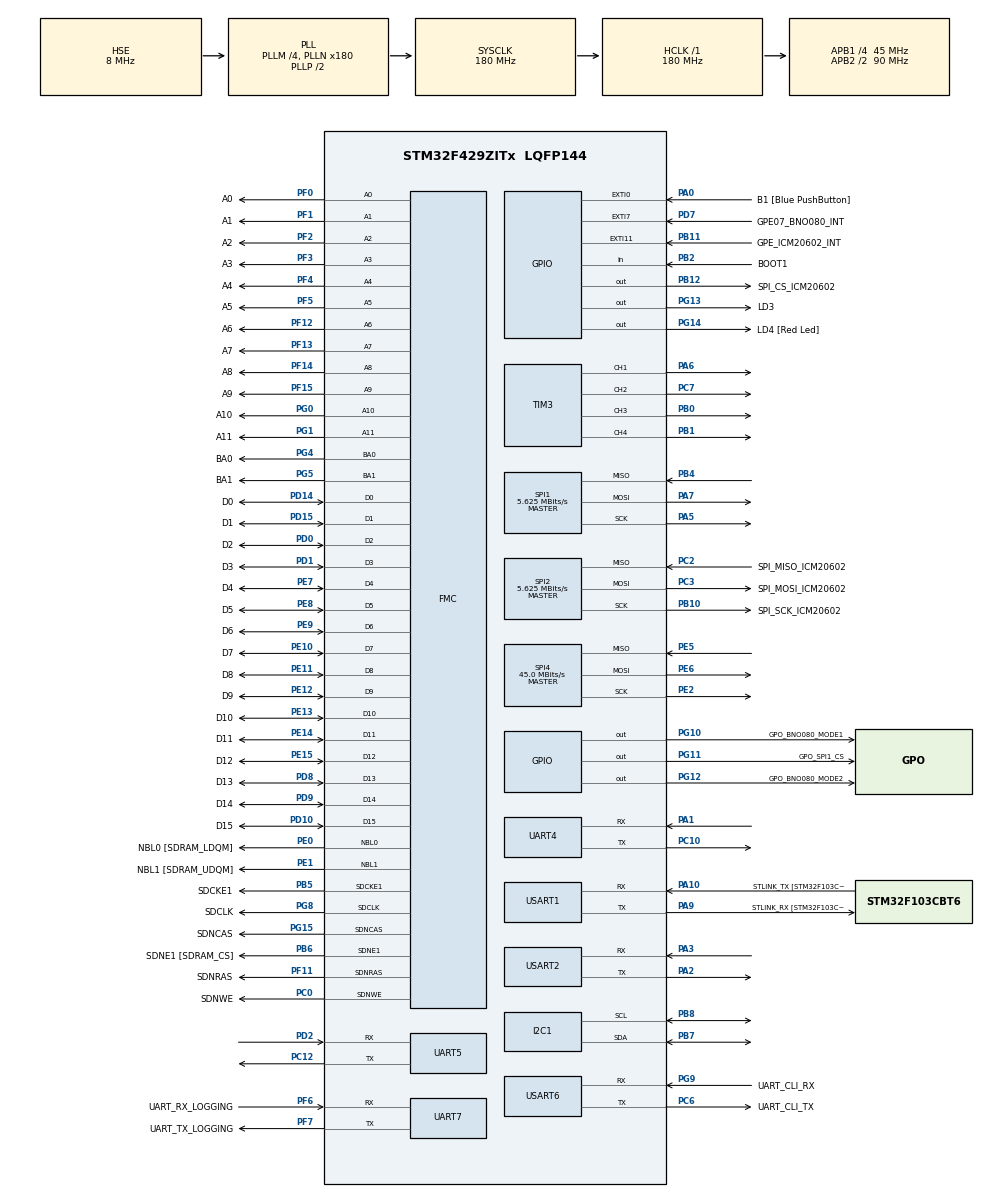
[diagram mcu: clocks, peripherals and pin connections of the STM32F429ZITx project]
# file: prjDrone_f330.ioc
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FMC.CASLatency1=FMC_SDRAM_CAS_LATENCY_3
FMC.ExitSelfRefreshDelay1=7
FMC.LoadToActiveDelay1=2
FMC.RCDDelay1=2
FMC.RPDelay1=2
FMC.RPDelay2=2
FMC.ReadBurst1=FMC_SDRAM_RBURST_DISABLE
FMC.ReadPipeDelay1=FMC_SDRAM_RPIPE_DELAY_1
FMC.ReadPipeDelay2=FMC_SDRAM_RPIPE_DELAY_1
FMC.RowCycleDelay1=7
FMC.RowCycleDelay2=7
FMC.SDClockPeriod1=FMC_SDRAM_CLOCK_PERIOD_2
FMC.SDClockPeriod2=FMC_SDRAM_CLOCK_PERIOD_2
FMC.SelfRefreshTime1=4
FMC.WriteRecoveryTime1=3
Mcu.Family=STM32F4
Mcu.Name=STM32F429ZITx
Mcu.Package=LQFP144
NVIC.EXTI9_5_IRQn=true\:5\:0\:true\:false\:true\:true\:true\:true
NVIC.PriorityGroup=NVIC_PRIORITYGROUP_4
NVIC.TIM7_IRQn=true\:5\:0\:true\:false\:true\:true\:true\:true
NVIC.USART6_IRQn=true\:5\:0\:true\:false\:true\:true\:true\:true
PA0/WKUP.GPIO_Label=B1 [Blue PushButton]
PA0/WKUP.GPIO_ModeDefaultEXTI=GPIO_MODE_EVT_RISING
PA0/WKUP.GPIO_PuPd=GPIO_NOPULL
PA0/WKUP.Signal=GPXTI0
PA1.Mode=Asynchronous
PA1.Signal=UART4_RX
PA10.GPIO_Label=STLINK_TX [STM32F103CBT6_PA2]
PA10.Mode=Asynchronous
PA10.Signal=USART1_RX
PA13.GPIO_Label=SWDIO
PA13.Mode=Serial_Wire
PA13.Signal=SYS_JTMS-SWDIO
PA14.GPIO_Label=SWCLK
PA14.Mode=Serial_Wire
PA14.Signal=SYS_JTCK-SWCLK
PA2.Mode=Asynchronous
PA2.Signal=USART2_TX
PA3.Mode=Asynchronous
PA3.Signal=USART2_RX
PA5.Mode=Full_Duplex_Master
PA5.Signal=SPI1_SCK
PA6.Signal=S_TIM3_CH1
PA7.Mode=Full_Duplex_Master
PA7.Signal=SPI1_MOSI
PA9.GPIO_Label=STLINK_RX [STM32F103CBT6_PA3]
PA9.Mode=Asynchronous
PA9.Signal=USART1_TX
PB0.Signal=S_TIM3_CH3
PB1.Signal=S_TIM3_CH4
PB10.GPIO_Label=SPI_SCK_ICM20602
PB10.Mode=Full_Duplex_Master
PB10.Signal=SPI2_SCK
PB11.GPIO_Label=GPE_ICM20602_INT
PB11.Signal=GPXTI11
PB12.GPIO_Label=SPI_CS_ICM20602
PB12.Signal=GPIO_Output
PB2/BOOT1.GPIO_Label=BOOT1
PB2/BOOT1.GPIO_Mode=GPIO_MODE_INPUT
PB2/BOOT1.GPIO_PuPd=GPIO_NOPULL
PB2/BOOT1.Signal=GPIO_Input
PB4.Mode=Full_Duplex_Master
PB4.Signal=SPI1_MISO
PB5.GPIO_Label=SDCKE1
PB5.GPIO_Mode=GPIO_MODE_AF_PP
PB5.GPIO_PuPd=GPIO_NOPULL
PB5.GPIO_Speed=GPIO_SPEED_FREQ_VERY_HIGH
PB5.Mode=SdramChipSelect2_1
PB5.Signal=FMC_SDCKE1
PB6.GPIO_Label=SDNE1 [SDRAM_CS]
PB6.GPIO_Mode=GPIO_MODE_AF_PP
PB6.GPIO_PuPd=GPIO_NOPULL
PB6.GPIO_Speed=GPIO_SPEED_FREQ_VERY_HIGH
PB6.Mode=SdramChipSelect2_1
PB6.Signal=FMC_SDNE1
PB7.Mode=I2C
PB7.Signal=I2C1_SDA
PB8.Mode=I2C
PB8.Signal=I2C1_SCL
PC0.GPIO_Label=SDNWE
PC0.GPIO_Mode=GPIO_MODE_AF_PP
PC0.GPIO_PuPd=GPIO_NOPULL
PC0.GPIO_Speed=GPIO_SPEED_FREQ_VERY_HIGH
PC0.Signal=FMC_SDNWE
PC10.Mode=Asynchronous
PC10.Signal=UART4_TX
PC12.Mode=Asynchronous
PC12.Signal=UART5_TX
PC2.GPIO_Label=SPI_MISO_ICM20602
PC2.Mode=Full_Duplex_Master
PC2.Signal=SPI2_MISO
PC3.GPIO_Label=SPI_MOSI_ICM20602
PC3.Mode=Full_Duplex_Master
PC3.Signal=SPI2_MOSI
PC6.GPIO_Label=UART_CLI_TX
PC6.Mode=Asynchronous
PC6.Signal=USART6_TX
PC7.Signal=S_TIM3_CH2
PD0.GPIO_Label=D2
PD0.GPIO_Mode=GPIO_MODE_AF_PP
PD0.GPIO_PuPd=GPIO_NOPULL
PD0.GPIO_Speed=GPIO_SPEED_FREQ_VERY_HIGH
PD0.Signal=FMC_D2_DA2
PD1.GPIO_Label=D3
PD1.GPIO_Mode=GPIO_MODE_AF_PP
PD1.GPIO_PuPd=GPIO_NOPULL
PD1.GPIO_Speed=GPIO_SPEED_FREQ_VERY_HIGH
PD1.Signal=FMC_D3_DA3
PD10.GPIO_Label=D15
PD10.GPIO_Mode=GPIO_MODE_AF_PP
PD10.GPIO_PuPd=GPIO_NOPULL
PD10.GPIO_Speed=GPIO_SPEED_FREQ_VERY_HIGH
PD10.Signal=FMC_D15_DA15
PD14.GPIO_Label=D0
PD14.GPIO_Mode=GPIO_MODE_AF_PP
PD14.GPIO_PuPd=GPIO_NOPULL
PD14.GPIO_Speed=GPIO_SPEED_FREQ_VERY_HIGH
PD14.Signal=FMC_D0_DA0
PD15.GPIO_Label=D1
PD15.GPIO_Mode=GPIO_MODE_AF_PP
PD15.GPIO_PuPd=GPIO_NOPULL
PD15.GPIO_Speed=GPIO_SPEED_FREQ_VERY_HIGH
PD15.Signal=FMC_D1_DA1
PD2.Mode=Asynchronous
PD2.Signal=UART5_RX
PD7.GPIO_Label=GPE07_BNO080_INT
PD7.Signal=GPXTI7
PD8.GPIO_Label=D13
PD8.GPIO_Mode=GPIO_MODE_AF_PP
PD8.GPIO_PuPd=GPIO_NOPULL
PD8.GPIO_Speed=GPIO_SPEED_FREQ_VERY_HIGH
PD8.Signal=FMC_D13_DA13
PD9.GPIO_Label=D14
PD9.GPIO_Mode=GPIO_MODE_AF_PP
PD9.GPIO_PuPd=GPIO_NOPULL
PD9.GPIO_Speed=GPIO_SPEED_FREQ_VERY_HIGH
PD9.Signal=FMC_D14_DA14
PE0.GPIO_Label=NBL0 [SDRAM_LDQM]
PE0.GPIO_Mode=GPIO_MODE_AF_PP
PE0.GPIO_PuPd=GPIO_NOPULL
PE0.GPIO_Speed=GPIO_SPEED_FREQ_VERY_HIGH
PE0.Signal=FMC_NBL0
PE1.GPIO_Label=NBL1 [SDRAM_UDQM]
PE1.GPIO_Mode=GPIO_MODE_AF_PP
PE1.GPIO_PuPd=GPIO_NOPULL
PE1.GPIO_Speed=GPIO_SPEED_FREQ_VERY_HIGH
PE1.Signal=FMC_NBL1
PE10.GPIO_Label=D7
PE10.GPIO_Mode=GPIO_MODE_AF_PP
PE10.GPIO_PuPd=GPIO_NOPULL
PE10.GPIO_Speed=GPIO_SPEED_FREQ_VERY_HIGH
PE10.Signal=FMC_D7_DA7
PE11.GPIO_Label=D8
PE11.GPIO_Mode=GPIO_MODE_AF_PP
PE11.GPIO_PuPd=GPIO_NOPULL
PE11.GPIO_Speed=GPIO_SPEED_FREQ_VERY_HIGH
PE11.Signal=FMC_D8_DA8
PE12.GPIO_Label=D9
PE12.GPIO_Mode=GPIO_MODE_AF_PP
PE12.GPIO_PuPd=GPIO_NOPULL
PE12.GPIO_Speed=GPIO_SPEED_FREQ_VERY_HIGH
PE12.Signal=FMC_D9_DA9
PE13.GPIO_Label=D10
PE13.GPIO_Mode=GPIO_MODE_AF_PP
PE13.GPIO_PuPd=GPIO_NOPULL
PE13.GPIO_Speed=GPIO_SPEED_FREQ_VERY_HIGH
PE13.Signal=FMC_D10_DA10
PE14.GPIO_Label=D11
PE14.GPIO_Mode=GPIO_MODE_AF_PP
PE14.GPIO_PuPd=GPIO_NOPULL
PE14.GPIO_Speed=GPIO_SPEED_FREQ_VERY_HIGH
PE14.Signal=FMC_D11_DA11
PE15.GPIO_Label=D12
PE15.GPIO_Mode=GPIO_MODE_AF_PP
PE15.GPIO_PuPd=GPIO_NOPULL
PE15.GPIO_Speed=GPIO_SPEED_FREQ_VERY_HIGH
PE15.Signal=FMC_D12_DA12
PE2.Mode=Full_Duplex_Master
PE2.Signal=SPI4_SCK
PE5.Mode=Full_Duplex_Master
PE5.Signal=SPI4_MISO
PE6.Mode=Full_Duplex_Master
PE6.Signal=SPI4_MOSI
PE7.GPIO_Label=D4
PE7.GPIO_Mode=GPIO_MODE_AF_PP
PE7.GPIO_PuPd=GPIO_NOPULL
PE7.GPIO_Speed=GPIO_SPEED_FREQ_VERY_HIGH
PE7.Signal=FMC_D4_DA4
PE8.GPIO_Label=D5
PE8.GPIO_Mode=GPIO_MODE_AF_PP
PE8.GPIO_PuPd=GPIO_NOPULL
PE8.GPIO_Speed=GPIO_SPEED_FREQ_VERY_HIGH
PE8.Signal=FMC_D5_DA5
PE9.GPIO_Label=D6
PE9.GPIO_Mode=GPIO_MODE_AF_PP
PE9.GPIO_PuPd=GPIO_NOPULL
PE9.GPIO_Speed=GPIO_SPEED_FREQ_VERY_HIGH
PE9.Signal=FMC_D6_DA6
PF0.GPIO_Label=A0
PF0.GPIO_Mode=GPIO_MODE_AF_PP
PF0.GPIO_PuPd=GPIO_NOPULL
PF0.GPIO_Speed=GPIO_SPEED_FREQ_VERY_HIGH
PF0.Signal=FMC_A0
PF1.GPIO_Label=A1
PF1.GPIO_Mode=GPIO_MODE_AF_PP
PF1.GPIO_PuPd=GPIO_NOPULL
PF1.GPIO_Speed=GPIO_SPEED_FREQ_VERY_HIGH
PF1.Signal=FMC_A1
PF11.GPIO_Label=SDNRAS
PF11.GPIO_Mode=GPIO_MODE_AF_PP
PF11.GPIO_PuPd=GPIO_NOPULL
PF11.GPIO_Speed=GPIO_SPEED_FREQ_VERY_HIGH
PF11.Signal=FMC_SDNRAS
PF12.GPIO_Label=A6
PF12.GPIO_Mode=GPIO_MODE_AF_PP
PF12.GPIO_PuPd=GPIO_NOPULL
PF12.GPIO_Speed=GPIO_SPEED_FREQ_VERY_HIGH
PF12.Signal=FMC_A6
PF13.GPIO_Label=A7
PF13.GPIO_Mode=GPIO_MODE_AF_PP
PF13.GPIO_PuPd=GPIO_NOPULL
PF13.GPIO_Speed=GPIO_SPEED_FREQ_VERY_HIGH
PF13.Signal=FMC_A7
PF14.GPIO_Label=A8
PF14.GPIO_Mode=GPIO_MODE_AF_PP
PF14.GPIO_PuPd=GPIO_NOPULL
PF14.GPIO_Speed=GPIO_SPEED_FREQ_VERY_HIGH
PF14.Signal=FMC_A8
PF15.GPIO_Label=A9
PF15.GPIO_Mode=GPIO_MODE_AF_PP
PF15.GPIO_PuPd=GPIO_NOPULL
PF15.GPIO_Speed=GPIO_SPEED_FREQ_VERY_HIGH
PF15.Signal=FMC_A9
PF2.GPIO_Label=A2
PF2.GPIO_Mode=GPIO_MODE_AF_PP
PF2.GPIO_PuPd=GPIO_NOPULL
PF2.GPIO_Speed=GPIO_SPEED_FREQ_VERY_HIGH
PF2.Signal=FMC_A2
PF3.GPIO_Label=A3
PF3.GPIO_Mode=GPIO_MODE_AF_PP
PF3.GPIO_PuPd=GPIO_NOPULL
PF3.GPIO_Speed=GPIO_SPEED_FREQ_VERY_HIGH
PF3.Signal=FMC_A3
PF4.GPIO_Label=A4
PF4.GPIO_Mode=GPIO_MODE_AF_PP
PF4.GPIO_PuPd=GPIO_NOPULL
PF4.GPIO_Speed=GPIO_SPEED_FREQ_VERY_HIGH
PF4.Signal=FMC_A4
PF5.GPIO_Label=A5
PF5.GPIO_Mode=GPIO_MODE_AF_PP
PF5.GPIO_PuPd=GPIO_NOPULL
PF5.GPIO_Speed=GPIO_SPEED_FREQ_VERY_HIGH
PF5.Signal=FMC_A5
PF6.GPIO_Label=UART_RX_LOGGING
PF6.Mode=Asynchronous
PF6.Signal=UART7_RX
PF7.GPIO_Label=UART_TX_LOGGING
PF7.Mode=Asynchronous
PF7.Signal=UART7_TX
PG0.GPIO_Label=A10
PG0.GPIO_Mode=GPIO_MODE_AF_PP
PG0.GPIO_PuPd=GPIO_NOPULL
PG0.GPIO_Speed=GPIO_SPEED_FREQ_VERY_HIGH
PG0.Signal=FMC_A10
PG1.GPIO_Label=A11
PG1.GPIO_Mode=GPIO_MODE_AF_PP
PG1.GPIO_PuPd=GPIO_NOPULL
PG1.GPIO_Speed=GPIO_SPEED_FREQ_VERY_HIGH
PG1.Signal=FMC_A11
PG10.GPIO_Label=GPO_BNO080_MODE1
PG10.Signal=GPIO_Output
PG11.GPIO_Label=GPO_SPI1_CS
PG11.Signal=GPIO_Output
PG12.GPIO_Label=GPO_BNO080_MODE2
PG12.Signal=GPIO_Output
PG13.GPIO_Label=LD3
PG13.Signal=GPIO_Output
PG14.GPIO_Label=LD4 [Red Led]
PG14.GPIO_PuPd=GPIO_NOPULL
PG14.GPIO_Speed=GPIO_SPEED_FREQ_LOW
PG14.Signal=GPIO_Output
PG15.GPIO_Label=SDNCAS
PG15.GPIO_Mode=GPIO_MODE_AF_PP
PG15.GPIO_PuPd=GPIO_NOPULL
PG15.GPIO_Speed=GPIO_SPEED_FREQ_VERY_HIGH
PG15.Signal=FMC_SDNCAS
PG4.GPIO_Label=BA0
PG4.GPIO_Mode=GPIO_MODE_AF_PP
PG4.GPIO_PuPd=GPIO_NOPULL
PG4.GPIO_Speed=GPIO_SPEED_FREQ_VERY_HIGH
PG4.Signal=FMC_A14_BA0
PG5.GPIO_Label=BA1
PG5.GPIO_Mode=GPIO_MODE_AF_PP
PG5.GPIO_PuPd=GPIO_NOPULL
PG5.GPIO_Speed=GPIO_SPEED_FREQ_VERY_HIGH
PG5.Signal=FMC_A15_BA1
PG8.GPIO_Label=SDCLK
PG8.GPIO_Mode=GPIO_MODE_AF_PP
PG8.GPIO_PuPd=GPIO_NOPULL
PG8.GPIO_Speed=GPIO_SPEED_FREQ_VERY_HIGH
PG8.Signal=FMC_SDCLK
PG9.GPIO_Label=UART_CLI_RX
PG9.Mode=Asynchronous
PG9.Signal=USART6_RX
PH0/OSC_IN.GPIO_Label=PH0-OSC_IN
PH0/OSC_IN.Mode=HSE-External-Oscillator
PH0/OSC_IN.Signal=RCC_OSC_IN
PH1/OSC_OUT.GPIO_Label=PH1-OSC_OUT
PH1/OSC_OUT.Mode=HSE-External-Oscillator
PH1/OSC_OUT.Signal=RCC_OSC_OUT
ProjectManager.HeapSize=0x200
ProjectManager.StackSize=0x400
ProjectManager.TargetToolchain=CMake
RCC.48MHZClocksFreq_Value=120000000
RCC.AHBFreq_Value=180000000
RCC.APB1CLKDivider=RCC_HCLK_DIV4
RCC.APB1Freq_Value=45000000
RCC.APB1TimFreq_Value=90000000
RCC.APB2CLKDivider=RCC_HCLK_DIV2
RCC.APB2Freq_Value=90000000
RCC.APB2TimFreq_Value=180000000
RCC.CortexFreq_Value=180000000
RCC.HCLKFreq_Value=180000000
RCC.HSE_VALUE=8000000
RCC.HSI_VALUE=16000000
RCC.LSE_VALUE=32768
RCC.PLLM=4
RCC.PLLN=180
RCC.PLLQ=3
RCC.PLLSAIN=50
RCC.PLLSourceVirtual=RCC_PLLSOURCE_HSE
RCC.SYSCLKFreq_VALUE=180000000
RCC.SYSCLKSource=RCC_SYSCLKSOURCE_PLLCLK
RCC.VCOOutputFreq_Value=360000000
SH.FMC_A0.0=FMC_A0,12b-sda1
SH.FMC_A1.0=FMC_A1,12b-sda1
SH.FMC_A10.0=FMC_A10,12b-sda1
SH.FMC_A11.0=FMC_A11,12b-sda1
SH.FMC_A14_BA0.0=FMC_BA0,FourSdramBanks1
SH.FMC_A15_BA1.0=FMC_BA1,FourSdramBanks1
SH.FMC_A2.0=FMC_A2,12b-sda1
SH.FMC_A3.0=FMC_A3,12b-sda1
SH.FMC_A4.0=FMC_A4,12b-sda1
SH.FMC_A5.0=FMC_A5,12b-sda1
SH.FMC_A6.0=FMC_A6,12b-sda1
SH.FMC_A7.0=FMC_A7,12b-sda1
SH.FMC_A8.0=FMC_A8,12b-sda1
SH.FMC_A9.0=FMC_A9,12b-sda1
SH.FMC_D0_DA0.0=FMC_D0,sd-16b-d1
SH.FMC_D10_DA10.0=FMC_D10,sd-16b-d1
SH.FMC_D11_DA11.0=FMC_D11,sd-16b-d1
SH.FMC_D12_DA12.0=FMC_D12,sd-16b-d1
SH.FMC_D13_DA13.0=FMC_D13,sd-16b-d1
SH.FMC_D14_DA14.0=FMC_D14,sd-16b-d1
SH.FMC_D15_DA15.0=FMC_D15,sd-16b-d1
SH.FMC_D1_DA1.0=FMC_D1,sd-16b-d1
SH.FMC_D2_DA2.0=FMC_D2,sd-16b-d1
SH.FMC_D3_DA3.0=FMC_D3,sd-16b-d1
SH.FMC_D4_DA4.0=FMC_D4,sd-16b-d1
SH.FMC_D5_DA5.0=FMC_D5,sd-16b-d1
SH.FMC_D6_DA6.0=FMC_D6,sd-16b-d1
SH.FMC_D7_DA7.0=FMC_D7,sd-16b-d1
SH.FMC_D8_DA8.0=FMC_D8,sd-16b-d1
SH.FMC_D9_DA9.0=FMC_D9,sd-16b-d1
SH.FMC_NBL0.0=FMC_NBL0,Sd2ByteEnable1
SH.FMC_NBL1.0=FMC_NBL1,Sd2ByteEnable1
SH.FMC_SDCLK.0=FMC_SDCLK,12b-sda1
SH.FMC_SDNCAS.0=FMC_SDNCAS,12b-sda1
SH.FMC_SDNRAS.0=FMC_SDNRAS,12b-sda1
SH.FMC_SDNWE.0=FMC_SDNWE,12b-sda1
SH.S_TIM3_CH1.0=TIM3_CH1,PWM Generation1 CH1
SH.S_TIM3_CH2.0=TIM3_CH2,PWM Generation2 CH2
SH.S_TIM3_CH3.0=TIM3_CH3,PWM Generation3 CH3
SH.S_TIM3_CH4.0=TIM3_CH4,PWM Generation4 CH4
SPI1.BaudRatePrescaler=SPI_BAUDRATEPRESCALER_16
SPI1.CLKPhase=SPI_PHASE_2EDGE
SPI1.CLKPolarity=SPI_POLARITY_HIGH
SPI1.CalculateBaudRate=5.625 MBits/s
SPI1.Direction=SPI_DIRECTION_2LINES
SPI1.Mode=SPI_MODE_MASTER
SPI1.VirtualType=VM_MASTER
SPI2.BaudRatePrescaler=SPI_BAUDRATEPRESCALER_8
SPI2.CLKPhase=SPI_PHASE_1EDGE
SPI2.CLKPolarity=SPI_POLARITY_LOW
SPI2.CalculateBaudRate=5.625 MBits/s
SPI2.Direction=SPI_DIRECTION_2LINES
SPI2.Mode=SPI_MODE_MASTER
SPI2.VirtualType=VM_MASTER
SPI4.CalculateBaudRate=45.0 MBits/s
SPI4.Direction=SPI_DIRECTION_2LINES
SPI4.Mode=SPI_MODE_MASTER
SPI4.VirtualType=VM_MASTER
TIM3.Channel-PWM\ Generation1\ CH1=TIM_CHANNEL_1
TIM3.Channel-PWM\ Generation2\ CH2=TIM_CHANNEL_2
TIM3.Channel-PWM\ Generation3\ CH3=TIM_CHANNEL_3
TIM3.Channel-PWM\ Generation4\ CH4=TIM_CHANNEL_4
TIM7.Period=1000-1
TIM7.Prescaler=90-1
UART4.VirtualMode=Asynchronous
UART5.VirtualMode=Asynchronous
UART7.VirtualMode=Asynchronous
USART1.VirtualMode=VM_ASYNC
USART2.VirtualMode=VM_ASYNC
USART6.VirtualMode=VM_ASYNC
VP_CRC_VS_CRC.Mode=CRC_Activate
VP_TIM3_VS_ClockSourceINT.Mode=Internal
VP_TIM6_VS_ClockSourceINT.Mode=Enable_Timer
VP_TIM7_VS_ClockSourceINT.Mode=Enable_Timer
board=STM32F429I-DISC1

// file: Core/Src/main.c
/* USER CODE BEGIN Header */
/**
  ******************************************************************************
  * @file           : main.c
  * @brief          : Main program body
  ******************************************************************************
  * @attention
  *
  * Copyright (c) 2025 STMicroelectronics.
  * All rights reserved.
  *
  * This software is licensed under terms that can be found in the LICENSE file
  * in the root directory of this software component.
  * If no LICENSE file comes with this software, it is provided AS-IS.
  *
  ******************************************************************************
  */

/* USER CODE END Header */
#include "main.h"

/* USER CODE BEGIN Includes */
#include "entry.h"
#include "tiny_printf.h"
#include "ICM20602.h"
#include "taskSensImu.h"
/* USER CODE END Includes */

CRC_HandleTypeDef hcrc;

I2C_HandleTypeDef hi2c1;

SPI_HandleTypeDef hspi1;
SPI_HandleTypeDef hspi2;
SPI_HandleTypeDef hspi4;

TIM_HandleTypeDef htim3;
TIM_HandleTypeDef htim6;
TIM_HandleTypeDef htim7;

UART_HandleTypeDef huart4;
UART_HandleTypeDef huart5;
UART_HandleTypeDef huart7;
UART_HandleTypeDef huart1;
UART_HandleTypeDef huart2;
UART_HandleTypeDef huart6;

SDRAM_HandleTypeDef hsdram1;

/* USER CODE BEGIN PV */
uint8_t g_ucKernelStarted = 0;

/* USER CODE END PV */

void SystemClock_Config(void);
static void MX_GPIO_Init(void);
static void MX_CRC_Init(void);
static void MX_FMC_Init(void);
static void MX_UART7_Init(void);
static void MX_USART1_UART_Init(void);
static void MX_USART6_UART_Init(void);
static void MX_TIM6_Init(void);
static void MX_TIM7_Init(void);
static void MX_I2C1_Init(void);
static void MX_SPI2_Init(void);
static void MX_UART4_Init(void);
static void MX_UART5_Init(void);
static void MX_USART2_UART_Init(void);
static void MX_SPI1_Init(void);
static void MX_TIM3_Init(void);
static void MX_SPI4_Init(void);

/* USER CODE BEGIN 0 */
void _putchar(char character)
{
  // send char to console etc.
  HAL_UART_Transmit(&huart1, (uint8_t*)(&character), 1, 20) ;
}
/* USER CODE END 0 */

int main(void)
{

  /* MCU Configuration--------------------------------------------------------*/

  /* Reset of all peripherals, Initializes the Flash interface and the Systick. */
  HAL_Init();

  /* Configure the system clock */
  SystemClock_Config();

  /* Initialize all configured peripherals */
  MX_GPIO_Init();
  MX_CRC_Init();
  MX_FMC_Init();
  MX_UART7_Init();
  MX_USART1_UART_Init();
  MX_USART6_UART_Init();
  MX_TIM6_Init();
  MX_TIM7_Init();
  MX_I2C1_Init();
  MX_SPI2_Init();
  MX_UART4_Init();
  MX_UART5_Init();
  MX_USART2_UART_Init();
  MX_SPI1_Init();
  MX_TIM3_Init();
  MX_SPI4_Init();
  /* USER CODE BEGIN 2 */

  HAL_GPIO_WritePin(SPI_CS_ICM20602_GPIO_Port, SPI_CS_ICM20602_Pin, GPIO_PIN_SET);
  HAL_Delay(1000);

  // while(1){
  //   HAL_Delay(5);
  //   ICM20602_Get3AxisGyroRawData(g_ausGyro);
  //   printf("X: %d, Y: %d, Z: %d\r\n",g_ausGyro[0], g_ausGyro[1],g_ausGyro[2] );
  // }

  EntryPoint();
  printf("Kernel Start Ready~\r\n");
  g_ucKernelStarted = 1;
  vTaskStartScheduler();

  /* USER CODE END 2 */

  /* Infinite loop */
  while (1)
  {

  }
}

void SystemClock_Config(void)
{
  RCC_OscInitTypeDef RCC_OscInitStruct = {0};
  RCC_ClkInitTypeDef RCC_ClkInitStruct = {0};

  /** Configure the main internal regulator output voltage
  */
  __HAL_RCC_PWR_CLK_ENABLE();
  __HAL_PWR_VOLTAGESCALING_CONFIG(PWR_REGULATOR_VOLTAGE_SCALE1);

  /** Initializes the RCC Oscillators according to the specified parameters
  * in the RCC_OscInitTypeDef structure.
  */
  RCC_OscInitStruct.OscillatorType = RCC_OSCILLATORTYPE_HSE;
  RCC_OscInitStruct.HSEState = RCC_HSE_ON;
  RCC_OscInitStruct.PLL.PLLState = RCC_PLL_ON;
  RCC_OscInitStruct.PLL.PLLSource = RCC_PLLSOURCE_HSE;
  RCC_OscInitStruct.PLL.PLLM = 4;
  RCC_OscInitStruct.PLL.PLLN = 180;
  RCC_OscInitStruct.PLL.PLLP = RCC_PLLP_DIV2;
  RCC_OscInitStruct.PLL.PLLQ = 3;
  if (HAL_RCC_OscConfig(&RCC_OscInitStruct) != HAL_OK)
  {
    Error_Handler();
  }

  /** Activate the Over-Drive mode
  */
  if (HAL_PWREx_EnableOverDrive() != HAL_OK)
  {
    Error_Handler();
  }

  /** Initializes the CPU, AHB and APB buses clocks
  */
  RCC_ClkInitStruct.ClockType = RCC_CLOCKTYPE_HCLK|RCC_CLOCKTYPE_SYSCLK
                              |RCC_CLOCKTYPE_PCLK1|RCC_CLOCKTYPE_PCLK2;
  RCC_ClkInitStruct.SYSCLKSource = RCC_SYSCLKSOURCE_PLLCLK;
  RCC_ClkInitStruct.AHBCLKDivider = RCC_SYSCLK_DIV1;
  RCC_ClkInitStruct.APB1CLKDivider = RCC_HCLK_DIV4;
  RCC_ClkInitStruct.APB2CLKDivider = RCC_HCLK_DIV2;

  if (HAL_RCC_ClockConfig(&RCC_ClkInitStruct, FLASH_LATENCY_5) != HAL_OK)
  {
    Error_Handler();
  }
}

static void MX_CRC_Init(void)
{

  hcrc.Instance = CRC;
  if (HAL_CRC_Init(&hcrc) != HAL_OK)
  {
    Error_Handler();
  }

}

static void MX_I2C1_Init(void)
{

  hi2c1.Instance = I2C1;
  hi2c1.Init.ClockSpeed = 100000;
  hi2c1.Init.DutyCycle = I2C_DUTYCYCLE_2;
  hi2c1.Init.OwnAddress1 = 0;
  hi2c1.Init.AddressingMode = I2C_ADDRESSINGMODE_7BIT;
  hi2c1.Init.DualAddressMode = I2C_DUALADDRESS_DISABLE;
  hi2c1.Init.OwnAddress2 = 0;
  hi2c1.Init.GeneralCallMode = I2C_GENERALCALL_DISABLE;
  hi2c1.Init.NoStretchMode = I2C_NOSTRETCH_DISABLE;
  if (HAL_I2C_Init(&hi2c1) != HAL_OK)
  {
    Error_Handler();
  }

  /** Configure Analogue filter
  */
  if (HAL_I2CEx_ConfigAnalogFilter(&hi2c1, I2C_ANALOGFILTER_ENABLE) != HAL_OK)
  {
    Error_Handler();
  }

  /** Configure Digital filter
  */
  if (HAL_I2CEx_ConfigDigitalFilter(&hi2c1, 0) != HAL_OK)
  {
    Error_Handler();
  }

}

static void MX_SPI1_Init(void)
{

  /* SPI1 parameter configuration*/
  hspi1.Instance = SPI1;
  hspi1.Init.Mode = SPI_MODE_MASTER;
  hspi1.Init.Direction = SPI_DIRECTION_2LINES;
  hspi1.Init.DataSize = SPI_DATASIZE_8BIT;
  hspi1.Init.CLKPolarity = SPI_POLARITY_HIGH;
  hspi1.Init.CLKPhase = SPI_PHASE_2EDGE;
  hspi1.Init.NSS = SPI_NSS_SOFT;
  hspi1.Init.BaudRatePrescaler = SPI_BAUDRATEPRESCALER_16;
  hspi1.Init.FirstBit = SPI_FIRSTBIT_MSB;
  hspi1.Init.TIMode = SPI_TIMODE_DISABLE;
  hspi1.Init.CRCCalculation = SPI_CRCCALCULATION_DISABLE;
  hspi1.Init.CRCPolynomial = 10;
  if (HAL_SPI_Init(&hspi1) != HAL_OK)
  {
    Error_Handler();
  }

}

static void MX_SPI2_Init(void)
{

  /* SPI2 parameter configuration*/
  hspi2.Instance = SPI2;
  hspi2.Init.Mode = SPI_MODE_MASTER;
  hspi2.Init.Direction = SPI_DIRECTION_2LINES;
  hspi2.Init.DataSize = SPI_DATASIZE_8BIT;
  hspi2.Init.CLKPolarity = SPI_POLARITY_LOW;
  hspi2.Init.CLKPhase = SPI_PHASE_1EDGE;
  hspi2.Init.NSS = SPI_NSS_SOFT;
  hspi2.Init.BaudRatePrescaler = SPI_BAUDRATEPRESCALER_8;
  hspi2.Init.FirstBit = SPI_FIRSTBIT_MSB;
  hspi2.Init.TIMode = SPI_TIMODE_DISABLE;
  hspi2.Init.CRCCalculation = SPI_CRCCALCULATION_DISABLE;
  hspi2.Init.CRCPolynomial = 10;
  if (HAL_SPI_Init(&hspi2) != HAL_OK)
  {
    Error_Handler();
  }

}

static void MX_SPI4_Init(void)
{

  /* SPI4 parameter configuration*/
  hspi4.Instance = SPI4;
  hspi4.Init.Mode = SPI_MODE_MASTER;
  hspi4.Init.Direction = SPI_DIRECTION_2LINES;
  hspi4.Init.DataSize = SPI_DATASIZE_8BIT;
  hspi4.Init.CLKPolarity = SPI_POLARITY_LOW;
  hspi4.Init.CLKPhase = SPI_PHASE_1EDGE;
  hspi4.Init.NSS = SPI_NSS_SOFT;
  hspi4.Init.BaudRatePrescaler = SPI_BAUDRATEPRESCALER_2;
  hspi4.Init.FirstBit = SPI_FIRSTBIT_MSB;
  hspi4.Init.TIMode = SPI_TIMODE_DISABLE;
  hspi4.Init.CRCCalculation = SPI_CRCCALCULATION_DISABLE;
  hspi4.Init.CRCPolynomial = 10;
  if (HAL_SPI_Init(&hspi4) != HAL_OK)
  {
    Error_Handler();
  }

}

static void MX_TIM3_Init(void)
{

  TIM_ClockConfigTypeDef sClockSourceConfig = {0};
  TIM_MasterConfigTypeDef sMasterConfig = {0};
  TIM_OC_InitTypeDef sConfigOC = {0};

  htim3.Instance = TIM3;
  htim3.Init.Prescaler = 0;
  htim3.Init.CounterMode = TIM_COUNTERMODE_UP;
  htim3.Init.Period = 65535;
  htim3.Init.ClockDivision = TIM_CLOCKDIVISION_DIV1;
  htim3.Init.AutoReloadPreload = TIM_AUTORELOAD_PRELOAD_DISABLE;
  if (HAL_TIM_Base_Init(&htim3) != HAL_OK)
  {
    Error_Handler();
  }
  sClockSourceConfig.ClockSource = TIM_CLOCKSOURCE_INTERNAL;
  if (HAL_TIM_ConfigClockSource(&htim3, &sClockSourceConfig) != HAL_OK)
  {
    Error_Handler();
  }
  if (HAL_TIM_PWM_Init(&htim3) != HAL_OK)
  {
    Error_Handler();
  }
  sMasterConfig.MasterOutputTrigger = TIM_TRGO_RESET;
  sMasterConfig.MasterSlaveMode = TIM_MASTERSLAVEMODE_DISABLE;
  if (HAL_TIMEx_MasterConfigSynchronization(&htim3, &sMasterConfig) != HAL_OK)
  {
    Error_Handler();
  }
  sConfigOC.OCMode = TIM_OCMODE_PWM1;
  sConfigOC.Pulse = 0;
  sConfigOC.OCPolarity = TIM_OCPOLARITY_HIGH;
  sConfigOC.OCFastMode = TIM_OCFAST_DISABLE;
  if (HAL_TIM_PWM_ConfigChannel(&htim3, &sConfigOC, TIM_CHANNEL_1) != HAL_OK)
  {
    Error_Handler();
  }
  if (HAL_TIM_PWM_ConfigChannel(&htim3, &sConfigOC, TIM_CHANNEL_2) != HAL_OK)
  {
    Error_Handler();
  }
  if (HAL_TIM_PWM_ConfigChannel(&htim3, &sConfigOC, TIM_CHANNEL_3) != HAL_OK)
  {
    Error_Handler();
  }
  if (HAL_TIM_PWM_ConfigChannel(&htim3, &sConfigOC, TIM_CHANNEL_4) != HAL_OK)
  {
    Error_Handler();
  }
  HAL_TIM_MspPostInit(&htim3);

}

static void MX_TIM6_Init(void)
{

  TIM_MasterConfigTypeDef sMasterConfig = {0};

  htim6.Instance = TIM6;
  htim6.Init.Prescaler = 0;
  htim6.Init.CounterMode = TIM_COUNTERMODE_UP;
  htim6.Init.Period = 65535;
  htim6.Init.AutoReloadPreload = TIM_AUTORELOAD_PRELOAD_DISABLE;
  if (HAL_TIM_Base_Init(&htim6) != HAL_OK)
  {
    Error_Handler();
  }
  sMasterConfig.MasterOutputTrigger = TIM_TRGO_RESET;
  sMasterConfig.MasterSlaveMode = TIM_MASTERSLAVEMODE_DISABLE;
  if (HAL_TIMEx_MasterConfigSynchronization(&htim6, &sMasterConfig) != HAL_OK)
  {
    Error_Handler();
  }

}

static void MX_TIM7_Init(void)
{

  TIM_MasterConfigTypeDef sMasterConfig = {0};

  htim7.Instance = TIM7;
  htim7.Init.Prescaler = 90-1;
  htim7.Init.CounterMode = TIM_COUNTERMODE_UP;
  htim7.Init.Period = 1000-1;
  htim7.Init.AutoReloadPreload = TIM_AUTORELOAD_PRELOAD_DISABLE;
  if (HAL_TIM_Base_Init(&htim7) != HAL_OK)
  {
    Error_Handler();
  }
  sMasterConfig.MasterOutputTrigger = TIM_TRGO_RESET;
  sMasterConfig.MasterSlaveMode = TIM_MASTERSLAVEMODE_DISABLE;
  if (HAL_TIMEx_MasterConfigSynchronization(&htim7, &sMasterConfig) != HAL_OK)
  {
    Error_Handler();
  }

}

static void MX_UART4_Init(void)
{

  huart4.Instance = UART4;
  huart4.Init.BaudRate = 115200;
  huart4.Init.WordLength = UART_WORDLENGTH_8B;
  huart4.Init.StopBits = UART_STOPBITS_1;
  huart4.Init.Parity = UART_PARITY_NONE;
  huart4.Init.Mode = UART_MODE_TX_RX;
  huart4.Init.HwFlowCtl = UART_HWCONTROL_NONE;
  huart4.Init.OverSampling = UART_OVERSAMPLING_16;
  if (HAL_UART_Init(&huart4) != HAL_OK)
  {
    Error_Handler();
  }

}

static void MX_UART5_Init(void)
{

  huart5.Instance = UART5;
  huart5.Init.BaudRate = 115200;
  huart5.Init.WordLength = UART_WORDLENGTH_8B;
  huart5.Init.StopBits = UART_STOPBITS_1;
  huart5.Init.Parity = UART_PARITY_NONE;
  huart5.Init.Mode = UART_MODE_TX_RX;
  huart5.Init.HwFlowCtl = UART_HWCONTROL_NONE;
  huart5.Init.OverSampling = UART_OVERSAMPLING_16;
  if (HAL_UART_Init(&huart5) != HAL_OK)
  {
    Error_Handler();
  }

}

static void MX_UART7_Init(void)
{

  huart7.Instance = UART7;
  huart7.Init.BaudRate = 115200;
  huart7.Init.WordLength = UART_WORDLENGTH_8B;
  huart7.Init.StopBits = UART_STOPBITS_1;
  huart7.Init.Parity = UART_PARITY_NONE;
  huart7.Init.Mode = UART_MODE_TX_RX;
  huart7.Init.HwFlowCtl = UART_HWCONTROL_NONE;
  huart7.Init.OverSampling = UART_OVERSAMPLING_16;
  if (HAL_UART_Init(&huart7) != HAL_OK)
  {
    Error_Handler();
  }

}

static void MX_USART1_UART_Init(void)
{

  huart1.Instance = USART1;
  huart1.Init.BaudRate = 115200;
  huart1.Init.WordLength = UART_WORDLENGTH_8B;
  huart1.Init.StopBits = UART_STOPBITS_1;
  huart1.Init.Parity = UART_PARITY_NONE;
  huart1.Init.Mode = UART_MODE_TX_RX;
  huart1.Init.HwFlowCtl = UART_HWCONTROL_NONE;
  huart1.Init.OverSampling = UART_OVERSAMPLING_16;
  if (HAL_UART_Init(&huart1) != HAL_OK)
  {
    Error_Handler();
  }

}

static void MX_USART2_UART_Init(void)
{

  huart2.Instance = USART2;
  huart2.Init.BaudRate = 115200;
  huart2.Init.WordLength = UART_WORDLENGTH_8B;
  huart2.Init.StopBits = UART_STOPBITS_1;
  huart2.Init.Parity = UART_PARITY_NONE;
  huart2.Init.Mode = UART_MODE_TX_RX;
  huart2.Init.HwFlowCtl = UART_HWCONTROL_NONE;
  huart2.Init.OverSampling = UART_OVERSAMPLING_16;
  if (HAL_UART_Init(&huart2) != HAL_OK)
  {
    Error_Handler();
  }

}

static void MX_USART6_UART_Init(void)
{

  huart6.Instance = USART6;
  huart6.Init.BaudRate = 115200;
  huart6.Init.WordLength = UART_WORDLENGTH_8B;
  huart6.Init.StopBits = UART_STOPBITS_1;
  huart6.Init.Parity = UART_PARITY_NONE;
  huart6.Init.Mode = UART_MODE_TX_RX;
  huart6.Init.HwFlowCtl = UART_HWCONTROL_NONE;
  huart6.Init.OverSampling = UART_OVERSAMPLING_16;
  if (HAL_UART_Init(&huart6) != HAL_OK)
  {
    Error_Handler();
  }

}

/* FMC initialization function */
static void MX_FMC_Init(void)
{

  FMC_SDRAM_TimingTypeDef SdramTiming = {0};

  /** Perform the SDRAM1 memory initialization sequence
  */
  hsdram1.Instance = FMC_SDRAM_DEVICE;
  /* hsdram1.Init */
  hsdram1.Init.SDBank = FMC_SDRAM_BANK2;
  hsdram1.Init.ColumnBitsNumber = FMC_SDRAM_COLUMN_BITS_NUM_8;
  hsdram1.Init.RowBitsNumber = FMC_SDRAM_ROW_BITS_NUM_12;
  hsdram1.Init.MemoryDataWidth = FMC_SDRAM_MEM_BUS_WIDTH_16;
  hsdram1.Init.InternalBankNumber = FMC_SDRAM_INTERN_BANKS_NUM_4;
  hsdram1.Init.CASLatency = FMC_SDRAM_CAS_LATENCY_3;
  hsdram1.Init.WriteProtection = FMC_SDRAM_WRITE_PROTECTION_DISABLE;
  hsdram1.Init.SDClockPeriod = FMC_SDRAM_CLOCK_PERIOD_2;
  hsdram1.Init.ReadBurst = FMC_SDRAM_RBURST_DISABLE;
  hsdram1.Init.ReadPipeDelay = FMC_SDRAM_RPIPE_DELAY_1;
  /* SdramTiming */
  SdramTiming.LoadToActiveDelay = 2;
  SdramTiming.ExitSelfRefreshDelay = 7;
  SdramTiming.SelfRefreshTime = 4;
  SdramTiming.RowCycleDelay = 7;
  SdramTiming.WriteRecoveryTime = 3;
  SdramTiming.RPDelay = 2;
  SdramTiming.RCDDelay = 2;

  if (HAL_SDRAM_Init(&hsdram1, &SdramTiming) != HAL_OK)
  {
    Error_Handler( );
  }

}

static void MX_GPIO_Init(void)
{
  GPIO_InitTypeDef GPIO_InitStruct = {0};

  /* GPIO Ports Clock Enable */
  __HAL_RCC_GPIOE_CLK_ENABLE();
  __HAL_RCC_GPIOF_CLK_ENABLE();
  __HAL_RCC_GPIOH_CLK_ENABLE();
  __HAL_RCC_GPIOC_CLK_ENABLE();
  __HAL_RCC_GPIOA_CLK_ENABLE();
  __HAL_RCC_GPIOB_CLK_ENABLE();
  __HAL_RCC_GPIOG_CLK_ENABLE();
  __HAL_RCC_GPIOD_CLK_ENABLE();

  /*Configure GPIO pin Output Level */
  HAL_GPIO_WritePin(SPI_CS_ICM20602_GPIO_Port, SPI_CS_ICM20602_Pin, GPIO_PIN_RESET);

  /*Configure GPIO pin Output Level */
  HAL_GPIO_WritePin(GPIOG, GPO_BNO080_MODE1_Pin|GPO_SPI1_CS_Pin|GPO_BNO080_MODE2_Pin|LD3_Pin
                          |LD4_Pin, GPIO_PIN_RESET);

  /*Configure GPIO pin : B1_Pin */
  GPIO_InitStruct.Pin = B1_Pin;
  GPIO_InitStruct.Mode = GPIO_MODE_EVT_RISING;
  GPIO_InitStruct.Pull = GPIO_NOPULL;
  HAL_GPIO_Init(B1_GPIO_Port, &GPIO_InitStruct);

  /*Configure GPIO pin : BOOT1_Pin */
  GPIO_InitStruct.Pin = BOOT1_Pin;
  GPIO_InitStruct.Mode = GPIO_MODE_INPUT;
  GPIO_InitStruct.Pull = GPIO_NOPULL;
  HAL_GPIO_Init(BOOT1_GPIO_Port, &GPIO_InitStruct);

  /*Configure GPIO pin : GPE_ICM20602_INT_Pin */
  GPIO_InitStruct.Pin = GPE_ICM20602_INT_Pin;
  GPIO_InitStruct.Mode = GPIO_MODE_IT_RISING;
  GPIO_InitStruct.Pull = GPIO_NOPULL;
  HAL_GPIO_Init(GPE_ICM20602_INT_GPIO_Port, &GPIO_InitStruct);

  /*Configure GPIO pin : SPI_CS_ICM20602_Pin */
  GPIO_InitStruct.Pin = SPI_CS_ICM20602_Pin;
  GPIO_InitStruct.Mode = GPIO_MODE_OUTPUT_PP;
  GPIO_InitStruct.Pull = GPIO_NOPULL;
  GPIO_InitStruct.Speed = GPIO_SPEED_FREQ_LOW;
  HAL_GPIO_Init(SPI_CS_ICM20602_GPIO_Port, &GPIO_InitStruct);

  /*Configure GPIO pin : GPE07_BNO080_INT_Pin */
  GPIO_InitStruct.Pin = GPE07_BNO080_INT_Pin;
  GPIO_InitStruct.Mode = GPIO_MODE_IT_RISING;
  GPIO_InitStruct.Pull = GPIO_NOPULL;
  HAL_GPIO_Init(GPE07_BNO080_INT_GPIO_Port, &GPIO_InitStruct);

  /*Configure GPIO pins : GPO_BNO080_MODE1_Pin GPO_SPI1_CS_Pin GPO_BNO080_MODE2_Pin LD3_Pin
                           LD4_Pin */
  GPIO_InitStruct.Pin = GPO_BNO080_MODE1_Pin|GPO_SPI1_CS_Pin|GPO_BNO080_MODE2_Pin|LD3_Pin
                          |LD4_Pin;
  GPIO_InitStruct.Mode = GPIO_MODE_OUTPUT_PP;
  GPIO_InitStruct.Pull = GPIO_NOPULL;
  GPIO_InitStruct.Speed = GPIO_SPEED_FREQ_LOW;
  HAL_GPIO_Init(GPIOG, &GPIO_InitStruct);

  /* EXTI interrupt init*/
  HAL_NVIC_SetPriority(EXTI9_5_IRQn, 5, 0);
  HAL_NVIC_EnableIRQ(EXTI9_5_IRQn);

  /* USER CODE BEGIN MX_GPIO_Init_2 */
  HAL_GPIO_WritePin(SPI_CS_ICM20602_GPIO_Port, SPI_CS_ICM20602_Pin, GPIO_PIN_SET);
  /* USER CODE END MX_GPIO_Init_2 */
}

void Error_Handler(void)
{
  __disable_irq();
  while (1)
  {
  }
}
